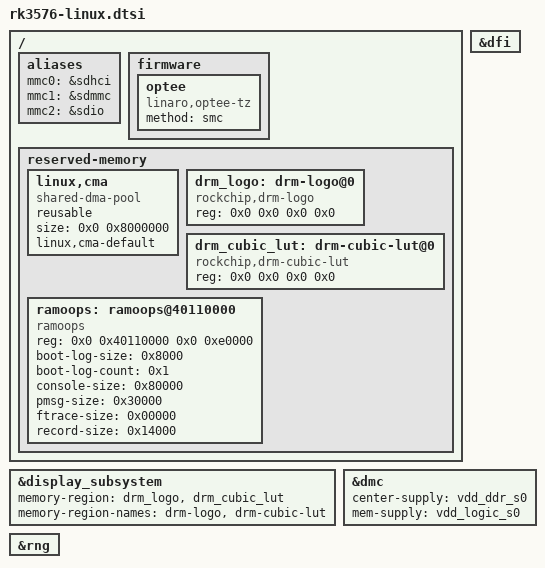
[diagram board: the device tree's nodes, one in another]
// SPDX-License-Identifier: (GPL-2.0+ OR MIT)
/*
 * Copyright (c) 2024 Rockchip Electronics Co., Ltd.
 *
 */

/ {
	aliases {
		mmc0 = &sdhci;
		mmc1 = &sdmmc;
		mmc2 = &sdio;
	};



	firmware {
		optee: optee {
			compatible = "linaro,optee-tz";
			method = "smc";
		};
	};

	reserved-memory {
		#address-cells = <2>;
		#size-cells = <2>;
		ranges;

		linux,cma {
			compatible = "shared-dma-pool";
			reusable;
			size = <0x0 0x8000000>; /* 128MB */
			linux,cma-default;
		};

		drm_logo: drm-logo@0 {
			compatible = "rockchip,drm-logo";
			reg = <0x0 0x0 0x0 0x0>;
		};

		drm_cubic_lut: drm-cubic-lut@0 {
			compatible = "rockchip,drm-cubic-lut";
			reg = <0x0 0x0 0x0 0x0>;
		};

		ramoops: ramoops@40110000 {
			compatible = "ramoops";
			/* 0x40110000 to 0x401f0000 is for ramoops */
			reg = <0x0 0x40110000 0x0 0xe0000>;
			boot-log-size = <0x8000>;	/* do not change */
			boot-log-count = <0x1>;		/* do not change */
			console-size = <0x80000>;
			pmsg-size = <0x30000>;
			ftrace-size = <0x00000>;
			record-size = <0x14000>;
		};
	};
};

&dfi {
	status = "okay";
};

&display_subsystem {
	memory-region = <&drm_logo>, <&drm_cubic_lut>;
	memory-region-names = "drm-logo", "drm-cubic-lut";
	/* devfreq = <&dmc>; */
};

&dmc {
	status = "okay";
	center-supply = <&vdd_ddr_s0>;
	mem-supply = <&vdd_logic_s0>;
};

&rng {
	status = "okay";
};
